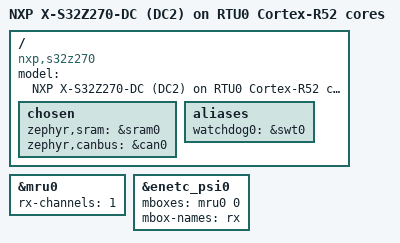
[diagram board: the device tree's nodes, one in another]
/*
 * Copyright 2022-2023 NXP
 *
 * SPDX-License-Identifier: Apache-2.0
 */

/dts-v1/;
#include <dt-bindings/clock/nxp_s32z2_clock.h>
#include <arm/nxp/nxp_s32z27x_rtu0_r52.dtsi>
#include "s32z270dc2_r52.dtsi"

/ {
	model = "NXP X-S32Z270-DC (DC2) on RTU0 Cortex-R52 cores";
	compatible = "nxp,s32z270";

	chosen {
		zephyr,sram = &sram0;
		zephyr,canbus = &can0;
	};

	aliases {
		watchdog0 = &swt0;
	};
};

&mru0 {
	rx-channels = <1>;
	status = "okay";
};

&enetc_psi0 {
	mboxes = <&mru0 0>;
	mbox-names = "rx";
};
